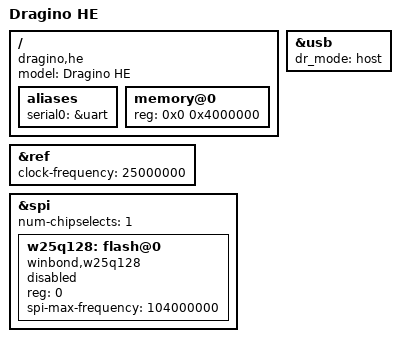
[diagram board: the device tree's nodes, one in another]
// SPDX-License-Identifier: GPL-2.0-only
/*
 * Dragino HE module
 *
 * Copyright (c) 2018-2019 Andreas Färber
 */

#include "ar9331.dtsi"

/ {
	compatible = "dragino,he", "qca,ar9331";
	model = "Dragino HE";

	aliases {
		serial0 = &uart;
	};

	memory@0 {
		device_type = "memory";
		reg = <0x0 0x4000000>; /* 64 MiB */
	};
};

&ref {
	clock-frequency = <25000000>;
};

/* internal */
&spi {
	status = "okay";
	num-chipselects = <1>;

	w25q128: flash@0 {
		compatible = "winbond,w25q128", "jedec,spi-nor";
		reg = <0>;
		spi-max-frequency = <104000000>;
		#address-cells = <1>;
		#size-cells = <1>;
		status = "disabled"; /* avoids null pointer dereference */
	};
};

&usb {
	dr_mode = "host";
};
